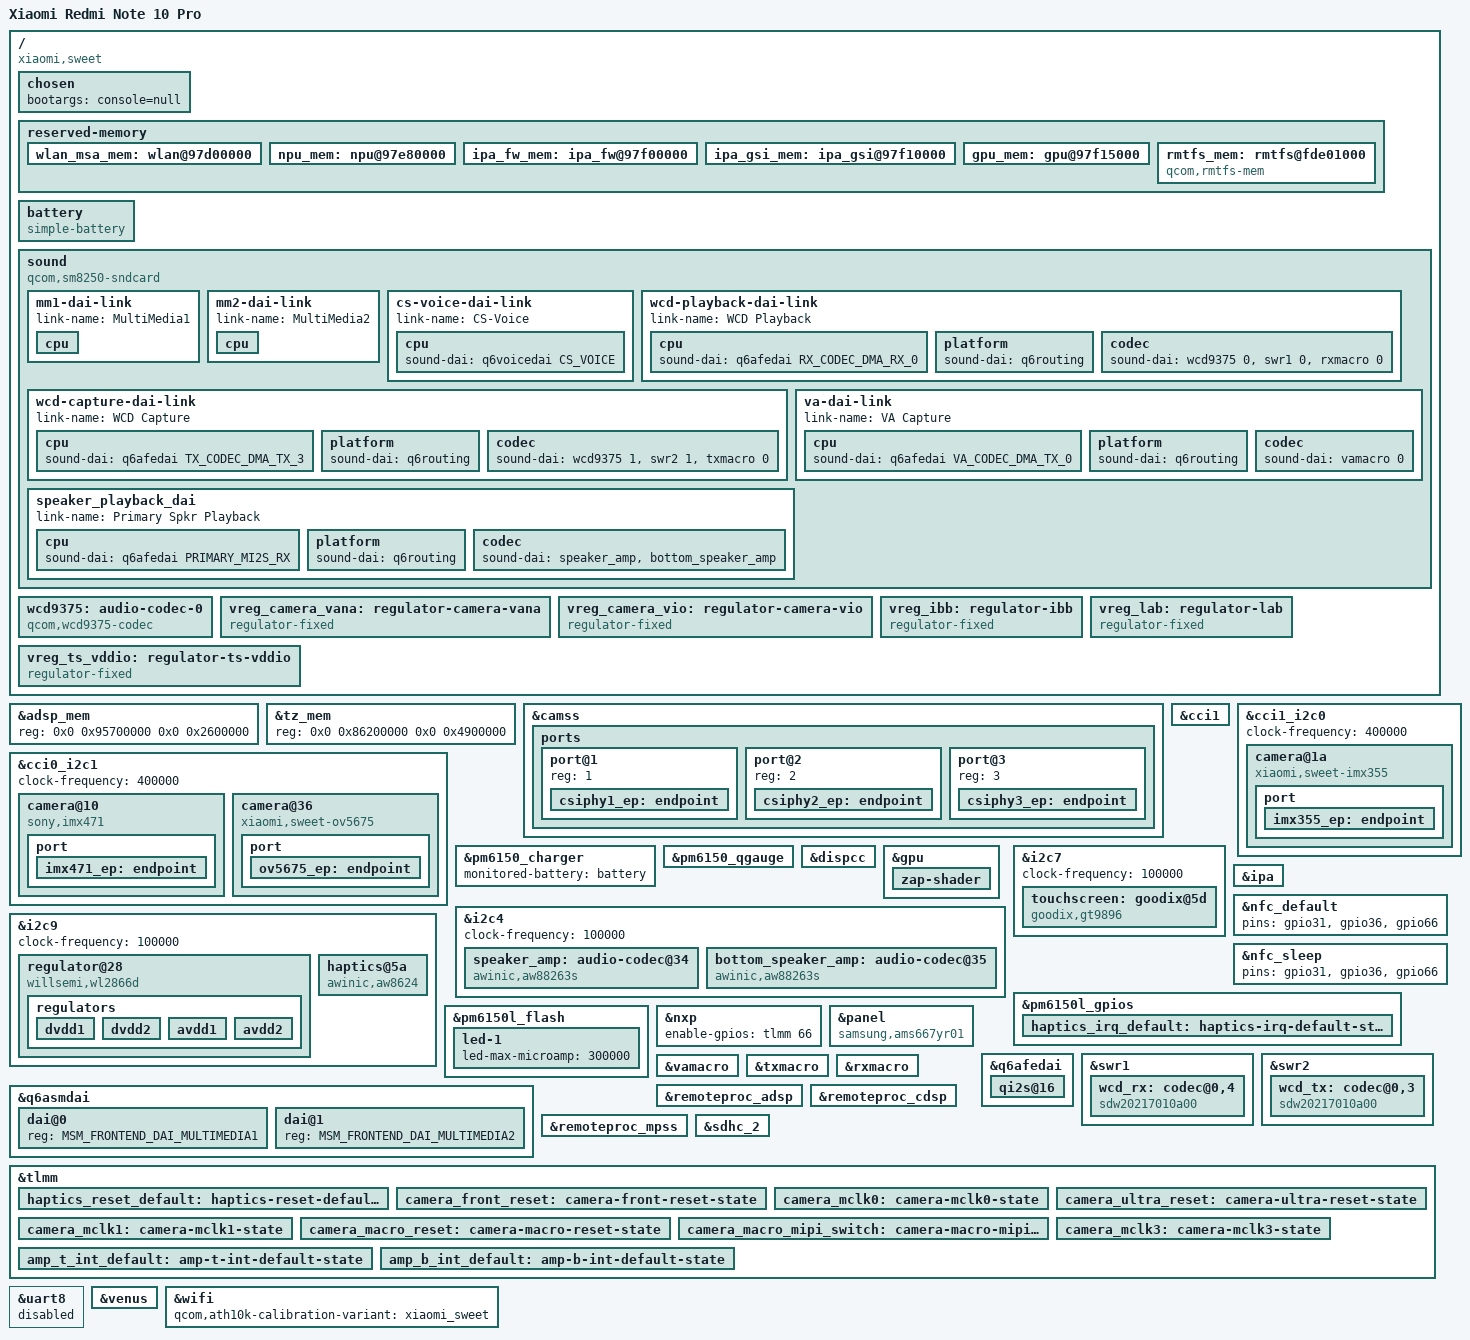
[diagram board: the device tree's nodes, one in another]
// SPDX-License-Identifier: BSD-3-Clause
/*
 * Copyright (c) 2024, Danila Tikhonov <danila@jiaxyga.com>
 * Copyright (c) 2024, Kali Prasad <kprasadvnsi@protonmail.com>
 * Copyright (c) 2024, Salvatore Stella <salvatore.stella@univaq.it>
 */

/dts-v1/;

#include <dt-bindings/sound/qcom,q6voice.h>

#include "sm7150-xiaomi-common.dtsi"

/delete-node/ &wlan_msa_mem;
/delete-node/ &npu_mem;
/delete-node/ &ipa_fw_mem;
/delete-node/ &ipa_gsi_mem;
/delete-node/ &gpu_mem;

&adsp_mem {
	reg = <0x0 0x95700000 0x0 0x2600000>;
};

&tz_mem {
	reg = <0x0 0x86200000 0x0 0x4900000>;
};

/ {
	model = "Xiaomi Redmi Note 10 Pro";
	compatible = "xiaomi,sweet", "qcom,sm7150";

	qcom,board-id = <46 0>;

	chosen {
		/*
		 * Serial engine with the debug UART operates in SPI mode on sweet
		 * So disable console and remove stdout-path
		 */
		/delete-property/ stdout-path;
		bootargs = "console=null";
	};

	reserved-memory {
		wlan_msa_mem: wlan@97d00000 {
			reg = <0x0 0x97d00000 0x0 0x180000>;
			no-map;
		};

		npu_mem: npu@97e80000 {
			reg = <0x0 0x97e80000 0x0 0x80000>;
			no-map;
		};

		ipa_fw_mem: ipa_fw@97f00000 {
			reg = <0x0 0x97f00000 0x0 0x10000>;
			no-map;
		};

		ipa_gsi_mem: ipa_gsi@97f10000 {
			reg = <0x0 0x97f10000 0x0 0x5000>;
			no-map;
		};

		gpu_mem: gpu@97f15000 {
			reg = <0x0 0x97f15000 0x0 0x2000>;
			no-map;
		};

		rmtfs_mem: rmtfs@fde01000 {
			compatible = "qcom,rmtfs-mem";
			reg = <0 0xfde01000 0 0x200000>;
			no-map;

			qcom,client-id = <1>;
			qcom,vmid = <QCOM_SCM_VMID_MSS_MSA>;
		};
	};

	battery: battery {
		compatible = "simple-battery";
		device-chemistry = "lithium-ion-polymer";
		voltage-min-design-microvolt = <3300000>;
		voltage-max-design-microvolt = <4450000>;
		constant-charge-voltage-max-microvolt = <4450000>;
		charge-full-design-microamp-hours = <5020000>;
		/* K6 Sunwoda 5020 mAh SOC_OCV2 profile, verified on sweet.
		 * Converted from the vendor profile: 100 uV and 0.01 percent.
		 */
		ocv-capacity-celsius = <(-10) 0 10 25 40 50>;
		ocv-capacity-table-0 = <4436500 100>, <4409100 98>, <4383600 96>, <4360600 94>,
			<4340100 92>, <4319000 90>, <4295300 88>, <4270400 86>,
			<4245400 84>, <4219900 82>, <4195300 80>, <4173100 78>,
			<4152000 76>, <4129100 74>, <4104000 72>, <4078000 70>,
			<4051600 68>, <4024700 66>, <3998800 64>, <3973200 62>,
			<3949200 60>, <3928400 58>, <3909600 56>, <3892000 54>,
			<3875400 52>, <3859700 50>, <3843800 48>, <3828300 46>,
			<3816900 44>, <3808900 42>, <3802500 40>, <3796600 38>,
			<3791400 36>, <3786000 34>, <3780600 32>, <3775000 30>,
			<3768600 28>, <3761700 26>, <3753900 24>, <3745000 22>,
			<3735300 20>, <3725500 18>, <3715500 16>, <3706300 14>,
			<3697600 12>, <3688500 10>, <3683300 9>, <3676800 8>,
			<3667800 7>, <3651800 6>, <3623000 5>, <3577800 4>,
			<3513100 3>, <3416100 2>, <3254400 1>, <2675700 0>;
		ocv-capacity-table-1 = <4435000 100>, <4408400 98>, <4383200 96>, <4359900 94>,
			<4338600 92>, <4316700 90>, <4292600 88>, <4267400 86>,
			<4242200 84>, <4216800 82>, <4192000 80>, <4168300 78>,
			<4145400 76>, <4122800 74>, <4100800 72>, <4079100 70>,
			<4058000 68>, <4037000 66>, <4013400 64>, <3985000 62>,
			<3957100 60>, <3933600 58>, <3912500 56>, <3893600 54>,
			<3876700 52>, <3861200 50>, <3846500 48>, <3832600 46>,
			<3820300 44>, <3808800 42>, <3799400 40>, <3793700 38>,
			<3789700 36>, <3786000 34>, <3782800 32>, <3779200 30>,
			<3774400 28>, <3767900 26>, <3760100 24>, <3750400 22>,
			<3739000 20>, <3726800 18>, <3713500 16>, <3701700 14>,
			<3691300 12>, <3681600 10>, <3675200 9>, <3667600 8>,
			<3656500 7>, <3640600 6>, <3612800 5>, <3570000 4>,
			<3508000 3>, <3418200 2>, <3261800 1>, <2828800 0>;
		ocv-capacity-table-2 = <4434000 100>, <4411300 98>, <4388900 96>, <4367200 94>,
			<4346400 92>, <4324800 90>, <4301100 88>, <4276600 86>,
			<4252000 84>, <4227300 82>, <4202800 80>, <4178700 78>,
			<4154900 76>, <4131500 74>, <4108600 72>, <4086300 70>,
			<4065500 68>, <4045200 66>, <4022700 64>, <3997000 62>,
			<3971300 60>, <3947300 58>, <3924600 56>, <3905300 54>,
			<3888800 52>, <3874000 50>, <3860700 48>, <3848600 46>,
			<3837500 44>, <3827200 42>, <3817700 40>, <3808500 38>,
			<3799800 36>, <3792000 34>, <3785100 32>, <3779000 30>,
			<3773800 28>, <3769300 26>, <3763400 24>, <3755300 22>,
			<3745200 20>, <3733200 18>, <3719000 16>, <3705300 14>,
			<3694200 12>, <3687500 10>, <3684300 9>, <3680900 8>,
			<3674400 7>, <3658900 6>, <3625100 5>, <3573200 4>,
			<3502700 3>, <3405800 2>, <3249000 1>, <2840100 0>;
		ocv-capacity-table-3 = <4433500 100>, <4411500 98>, <4389800 96>, <4368500 94>,
			<4347800 92>, <4326300 90>, <4302900 88>, <4278600 86>,
			<4254100 84>, <4229300 82>, <4204600 80>, <4180300 78>,
			<4156200 76>, <4132700 74>, <4109800 72>, <4087400 70>,
			<4065800 68>, <4044800 66>, <4024300 64>, <4004700 62>,
			<3983500 60>, <3957100 58>, <3929400 56>, <3908400 54>,
			<3891700 52>, <3877100 50>, <3864000 48>, <3852300 46>,
			<3841500 44>, <3831500 42>, <3822300 40>, <3813600 38>,
			<3805600 36>, <3798100 34>, <3791400 32>, <3784300 30>,
			<3775500 28>, <3766000 26>, <3757000 24>, <3748500 22>,
			<3739200 20>, <3728000 18>, <3715600 16>, <3701600 14>,
			<3692700 12>, <3688900 10>, <3687300 9>, <3685000 8>,
			<3679200 7>, <3658100 6>, <3615000 5>, <3558600 4>,
			<3484400 3>, <3378900 2>, <3209400 1>, <2692400 0>;
		ocv-capacity-table-4 = <4428000 100>, <4406400 98>, <4385000 96>, <4363800 94>,
			<4343100 92>, <4321600 90>, <4298400 88>, <4274200 86>,
			<4249900 84>, <4225300 82>, <4200900 80>, <4176700 78>,
			<4152900 76>, <4129500 74>, <4106800 72>, <4084700 70>,
			<4063200 68>, <4042300 66>, <4022300 64>, <4003500 62>,
			<3983400 60>, <3957800 58>, <3930200 56>, <3909100 54>,
			<3892400 52>, <3878000 50>, <3865000 48>, <3853400 46>,
			<3842800 44>, <3833000 42>, <3824000 40>, <3816000 38>,
			<3808500 36>, <3800500 34>, <3792000 32>, <3782900 30>,
			<3772600 28>, <3761500 26>, <3751300 24>, <3742100 22>,
			<3732600 20>, <3721500 18>, <3709400 16>, <3695700 14>,
			<3687300 12>, <3684400 10>, <3683200 9>, <3680900 8>,
			<3674100 7>, <3648000 6>, <3604000 5>, <3547000 4>,
			<3472300 3>, <3366400 2>, <3202400 1>, <2661500 0>;
		ocv-capacity-table-5 = <4426000 100>, <4404500 98>, <4383100 96>, <4362100 94>,
			<4341300 92>, <4319900 90>, <4296900 88>, <4273000 86>,
			<4248900 84>, <4224400 82>, <4199900 80>, <4175800 78>,
			<4152000 76>, <4128700 74>, <4105800 72>, <4083600 70>,
			<4062400 68>, <4041900 66>, <4022100 64>, <4003500 62>,
			<3983500 60>, <3958300 58>, <3930900 56>, <3909700 54>,
			<3893300 52>, <3878900 50>, <3865900 48>, <3854100 46>,
			<3843300 44>, <3833100 42>, <3823800 40>, <3815600 38>,
			<3808000 36>, <3799600 34>, <3790200 32>, <3780200 30>,
			<3768800 28>, <3756600 26>, <3745800 24>, <3736600 22>,
			<3727200 20>, <3715700 18>, <3703000 16>, <3689400 14>,
			<3681300 12>, <3678700 10>, <3677400 9>, <3675000 8>,
			<3665900 7>, <3637700 6>, <3592000 5>, <3534500 4>,
			<3458600 3>, <3353200 2>, <3168900 1>, <2657400 0>;
	};

	sound {
		compatible = "qcom,sm8250-sndcard";
		pinctrl-0 = <&pri_mi2s_active &pri_mi2s_ws_active>;
		pinctrl-names = "default";
		model = "Redmi Note 10 Pro";
		audio-routing = "AMIC1", "MIC BIAS1",
				"AMIC2", "MIC BIAS2",
				"AMIC3", "MIC BIAS3",
				/* bolero RX macro -> WCD9375 analog inputs */
				"IN1_HPHL", "HPHL_OUT",
				"IN2_HPHR", "HPHR_OUT",
				"IN3_AUX", "AUX_OUT",
				"TX SWR_ADC0", "ADC1_OUTPUT",
				"TX SWR_ADC2", "ADC2_OUTPUT";

		mm1-dai-link {
			link-name = "MultiMedia1";
			cpu {
				sound-dai = <&q6asmdai MSM_FRONTEND_DAI_MULTIMEDIA1>;
			};
		};

		mm2-dai-link {
			link-name = "MultiMedia2";
			cpu {
				sound-dai = <&q6asmdai MSM_FRONTEND_DAI_MULTIMEDIA2>;
			};
		};

		cs-voice-dai-link {
			link-name = "CS-Voice";
			cpu {
				sound-dai = <&q6voicedai CS_VOICE>;
			};
		};

		wcd-playback-dai-link {
			link-name = "WCD Playback";
			cpu {
				sound-dai = <&q6afedai RX_CODEC_DMA_RX_0>;
			};

			platform {
				sound-dai = <&q6routing>;
			};

			codec {
				sound-dai = <&wcd9375 0>, <&swr1 0>, <&rxmacro 0>;
			};
		};

		wcd-capture-dai-link {
			link-name = "WCD Capture";
			cpu {
				sound-dai = <&q6afedai TX_CODEC_DMA_TX_3>;
			};

			platform {
				sound-dai = <&q6routing>;
			};

			codec {
				sound-dai = <&wcd9375 1>, <&swr2 1>, <&txmacro 0>;
			};
		};

		va-dai-link {
			link-name = "VA Capture";
			cpu {
				sound-dai = <&q6afedai VA_CODEC_DMA_TX_0>;
			};

			platform {
				sound-dai = <&q6routing>;
			};

			codec {
				sound-dai = <&vamacro 0>;
			};
		};

		speaker_playback_dai {
			link-name = "Primary Spkr Playback";
			cpu {
				sound-dai = <&q6afedai PRIMARY_MI2S_RX>;
			};

			platform {
				sound-dai = <&q6routing>;
			};

			codec {
				sound-dai = <&speaker_amp>, <&bottom_speaker_amp>;
			};
		};
	};

	wcd9375: audio-codec-0 {
		compatible = "qcom,wcd9375-codec";

		reset-gpios = <&lpass_tlmm 6 GPIO_ACTIVE_LOW>;

		vdd-buck-supply = <&vreg_l15a_1p8>;
		vdd-rxtx-supply = <&vreg_l10a_1p8>;
		vdd-px-supply = <&vreg_l10a_1p8>;
		vdd-mic-bias-supply = <&vreg_bob>;

		qcom,micbias1-microvolt = <2750000>;
		qcom,micbias2-microvolt = <2750000>;
		qcom,micbias3-microvolt = <2750000>;
		qcom,mbhc-buttons-vthreshold-microvolt =
			<75000 150000 237000 500000 500000 500000 500000 500000>;

		qcom,rx-device = <&wcd_rx>;
		qcom,tx-device = <&wcd_tx>;

		#sound-dai-cells = <1>;
	};

	vreg_camera_vana: regulator-camera-vana {
		compatible = "regulator-fixed";
		regulator-name = "camera-vana";
		regulator-min-microvolt = <2800000>;
		regulator-max-microvolt = <2800000>;
		vin-supply = <&vreg_bob>;
		gpio = <&pm6150l_gpios 11 GPIO_ACTIVE_HIGH>;
		enable-active-high;
		startup-delay-us = <100>;
	};

	vreg_camera_vio: regulator-camera-vio {
		compatible = "regulator-fixed";
		regulator-name = "camera-vio";
		regulator-min-microvolt = <1800000>;
		regulator-max-microvolt = <1800000>;
		vin-supply = <&vreg_s5a_2p0>;
		gpio = <&pm6150l_gpios 4 GPIO_ACTIVE_HIGH>;
		enable-active-high;
		startup-delay-us = <100>;
	};

	vreg_ibb: regulator-ibb {
		compatible = "regulator-fixed";
		regulator-name = "ibb";
		regulator-min-microvolt = <6000000>;
		regulator-max-microvolt = <6000000>;
	};

	vreg_lab: regulator-lab {
		compatible = "regulator-fixed";
		regulator-name = "lab";
		regulator-min-microvolt = <6000000>;
		regulator-max-microvolt = <6000000>;
	};

	vreg_ts_vddio: regulator-ts-vddio {
		compatible = "regulator-fixed";
		regulator-name = "vreg_ts_vddio";
		regulator-min-microvolt = <1800000>;
		regulator-max-microvolt = <1800000>;
		gpio = <&tlmm 90 GPIO_ACTIVE_HIGH>;
		enable-active-high;
		regulator-boot-on;
		startup-delay-us = <4000>;
	};
};

&camss {
	ports {
		#address-cells = <1>;
		#size-cells = <0>;

		port@1 {
			reg = <1>;

			csiphy1_ep: endpoint {
				data-lanes = <0 1 2 3>;
				remote-endpoint = <&imx471_ep>;
			};
		};

		port@2 {
			reg = <2>;

			csiphy2_ep: endpoint {
				data-lanes = <0 1 2 3>;
				remote-endpoint = <&imx355_ep>;
			};
		};

		port@3 {
			reg = <3>;

			csiphy3_ep: endpoint {
				data-lanes = <0 1>;
				remote-endpoint = <&ov5675_ep>;
			};
		};
	};
};

&cci0_i2c1 {
	clock-frequency = <400000>;

	camera@10 {
		compatible = "sony,imx471";
		reg = <0x10>;

		clocks = <&camcc CAMCC_MCLK0_CLK>;
		assigned-clocks = <&camcc CAMCC_MCLK0_CLK>;
		assigned-clock-rates = <19200000>;

		reset-gpios = <&tlmm 23 GPIO_ACTIVE_LOW>;
		vana-supply = <&vreg_camera_vana>;
		dovdd-supply = <&vreg_camera_vio>;
		dvdd-supply = <&dvdd2>;

		pinctrl-names = "default";
		pinctrl-0 = <&camera_front_reset &camera_mclk0>;

		orientation = <0>;
		rotation = <90>;

		port {
			imx471_ep: endpoint {
				data-lanes = <0 1 2 3>;
				link-frequencies = /bits/ 64 <702933333>;
				remote-endpoint = <&csiphy1_ep>;
			};
		};
	};

	camera@36 {
		compatible = "xiaomi,sweet-ov5675", "ovti,ov5675";
		reg = <0x36>;

		clocks = <&camcc CAMCC_MCLK3_CLK>;
		assigned-clocks = <&camcc CAMCC_MCLK3_CLK>;
		assigned-clock-rates = <19200000>;

		reset-gpios = <&tlmm 24 GPIO_ACTIVE_LOW>;
		mipi-switch-gpios = <&tlmm 88 GPIO_ACTIVE_HIGH>;
		avdd-supply = <&vreg_camera_vana>;
		dovdd-supply = <&vreg_camera_vio>;
		dvdd-supply = <&dvdd1>;

		pinctrl-names = "default";
		pinctrl-0 = <&camera_macro_reset &camera_macro_mipi_switch
			     &camera_mclk3>;

		orientation = <1>;
		rotation = <270>;

		port {
			ov5675_ep: endpoint {
				data-lanes = <0 1>;
				link-frequencies = /bits/ 64 <450000000>;
				remote-endpoint = <&csiphy3_ep>;
			};
		};
	};
};

&cci1 {
	status = "okay";
};

&cci1_i2c0 {
	clock-frequency = <400000>;

	camera@1a {
		compatible = "xiaomi,sweet-imx355", "sony,imx355";
		reg = <0x1a>;

		clocks = <&camcc CAMCC_MCLK1_CLK>;
		assigned-clocks = <&camcc CAMCC_MCLK1_CLK>;
		assigned-clock-rates = <19200000>;

		reset-gpios = <&tlmm 25 GPIO_ACTIVE_LOW>;
		avdd-supply = <&avdd2>;
		dvdd-supply = <&dvdd1>;
		dovdd-supply = <&vreg_camera_vio>;

		pinctrl-names = "default";
		pinctrl-0 = <&camera_ultra_reset &camera_mclk1>;

		orientation = <1>;
		rotation = <270>;

		port {
			imx355_ep: endpoint {
				data-lanes = <0 1 2 3>;
				link-frequencies = /bits/ 64 <345600000>;
				remote-endpoint = <&csiphy2_ep>;
			};
		};
	};
};

&pm6150_charger {
	monitored-battery = <&battery>;
	status = "okay";
};

&pm6150_qgauge {
	monitored-battery = <&battery>;
	power-supplies = <&pm6150_charger>;
	status = "okay";
};

&dispcc {
	status = "okay";
};

&gpu {
	zap-shader {
		firmware-name = "qcom/sm7150/xiaomi/sweet/a615_zap.mbn";
	};
};

&i2c4 {
	clock-frequency = <100000>;
	status = "okay";

	/* Top speaker */
        speaker_amp: audio-codec@34 {
		compatible = "awinic,aw88263s";
		reg = <0x34>;
		firmware-name = "qcom/sm7150/xiaomi/sweet/aw882xx_pid_2032_acf.bin";

		reset-gpios = <&tlmm 64 GPIO_ACTIVE_HIGH>;

		pinctrl-names = "default";
		pinctrl-0 = <&amp_t_int_default>;

		awinic,audio-channel = <0>;
		awinic,sync-flag;

		sound-name-prefix = "Speaker";
		#sound-dai-cells = <0>;
        };

	/* Bottom speaker */
	bottom_speaker_amp: audio-codec@35 {
		compatible = "awinic,aw88263s";
		reg = <0x35>;
		firmware-name = "qcom/sm7150/xiaomi/sweet/aw882xx_pid_2032_acf.bin";

		reset-gpios = <&tlmm 72 GPIO_ACTIVE_HIGH>;

		pinctrl-names = "default";
		pinctrl-0 = <&amp_b_int_default>;

		awinic,audio-channel = <1>;
		awinic,sync-flag;

		sound-name-prefix = "Bottom Speaker";
		#sound-dai-cells = <0>;
        };
};

&i2c7 {
	clock-frequency = <100000>;
	status = "okay";

	touchscreen: goodix@5d {
		compatible = "goodix,gt9896";
		reg = <0x5d>;
		interrupts-extended = <&tlmm 9 IRQ_TYPE_LEVEL_LOW>;
		reset-gpios = <&tlmm 8 GPIO_ACTIVE_LOW>;
		avdd-supply = <&vreg_l11c_3p3>;
		vddio-supply = <&vreg_ts_vddio>;
		touchscreen-size-x = <1080>;
		touchscreen-size-y = <2400>;
	};
};

&i2c9 {
	clock-frequency = <100000>;
	status = "okay";

	regulator@28 {
		compatible = "willsemi,wl2866d";
		reg = <0x28>;

		vin1-supply = <&vreg_s8c_1p35>;
		vin2-supply = <&vreg_bob>;
		enable-gpios = <&tlmm 30 GPIO_ACTIVE_HIGH>;

		regulators {
			dvdd1: dvdd1 {
				regulator-name = "wl2866d-dvdd1";
				regulator-min-microvolt = <1200000>;
				regulator-max-microvolt = <1200000>;
				regulator-active-discharge = <1>;
			};

			dvdd2: dvdd2 {
				regulator-name = "wl2866d-dvdd2";
				regulator-min-microvolt = <1050000>;
				regulator-max-microvolt = <1050000>;
				regulator-active-discharge = <1>;
			};

			avdd1: avdd1 {
				regulator-name = "wl2866d-avdd1";
				regulator-min-microvolt = <2800000>;
				regulator-max-microvolt = <2800000>;
				regulator-active-discharge = <1>;
			};

			avdd2: avdd2 {
				regulator-name = "wl2866d-avdd2";
				regulator-min-microvolt = <2700000>;
				regulator-max-microvolt = <2700000>;
				regulator-active-discharge = <1>;
			};
		};
	};

	haptics@5a {
		compatible = "awinic,aw8624";
		reg = <0x5a>;
		interrupts-extended = <&pm6150l_gpios 10 IRQ_TYPE_EDGE_FALLING>;
		reset-gpios = <&tlmm 4 GPIO_ACTIVE_LOW>;

		pinctrl-names = "default";
		pinctrl-0 = <&haptics_reset_default &haptics_irq_default>;

		awinic,f0-preset = <2050>;
		awinic,f0-calibration-percent = <7>;
		awinic,drive-level = <106>;
		awinic,overdrive-level = <155>;
		awinic,drive-time = <0xf06c>;
		awinic,zero-cross-threshold = <0x08f8>;
		awinic,brake-cycles = <3>;
		awinic,tset = <0x11>;
		awinic,bemf-upper-threshold = <0x0008>;
		awinic,bemf-lower-threshold = <0x03f8>;
		awinic,f0-trace-parameters = <9 5 1 15>;
	};

	/* lionsemi,ln8000 (charger) @ 51 */
	/* ti,bq2597x (charger) @ 66 */
};

&ipa {
	firmware-name = "qcom/sm7150/xiaomi/sweet/ipa_fws.mbn";
};

&nfc_default {
	pins = "gpio31", "gpio36", "gpio66";
};

&nfc_sleep {
	pins = "gpio31", "gpio36", "gpio66";
};

&pm6150l_gpios {
	haptics_irq_default: haptics-irq-default-state {
		pins = "gpio10";
		function = PMIC_GPIO_FUNC_NORMAL;
		input-enable;
		bias-pull-up;
		power-source = <1>;
		qcom,pull-up-strength = <PMIC_GPIO_PULL_UP_31P5>;
	};
};

&pm6150l_flash {
	status = "okay";

	led-1 {
		led-max-microamp = <300000>;
	};
};

&nxp {
	enable-gpios = <&tlmm 66 GPIO_ACTIVE_HIGH>;
};

&panel {
	compatible = "samsung,ams667yr01";

	vsn-supply = <&vreg_ibb>;
	vsp-supply = <&vreg_lab>;
};

&q6afedai {
	qi2s@16 {
		reg = <PRIMARY_MI2S_RX>;
		qcom,sd-lines = <0>;
	};
};

&q6asmdai {
	dai@0 {
		reg = <MSM_FRONTEND_DAI_MULTIMEDIA1>;
	};

	dai@1 {
		reg = <MSM_FRONTEND_DAI_MULTIMEDIA2>;
	};
};

&swr1 {
	status = "okay";

	wcd_rx: codec@0,4 {
		compatible = "sdw20217010a00";
		reg = <0 4>;

		qcom,rx-port-mapping = <1 2 3 4 5>;
		qcom,rx-channel-mapping = /bits/ 8 <1 2 1 1 2 1 1 2>;
	};
};

&swr2 {
	status = "okay";

	wcd_tx: codec@0,3 {
		compatible = "sdw20217010a00";
		reg = <0 3>;

		qcom,tx-port-mapping = <2 2 3 4>;
		qcom,tx-channel-mapping = /bits/ 8 <1 2 1 1 2 3 3 4 1 2 3 4>;
	};
};

&vamacro {
	status = "okay";
};

&txmacro {
	status = "okay";
};

&rxmacro {
	status = "okay";
};

&remoteproc_adsp {
	firmware-name = "qcom/sm7150/xiaomi/sweet/adsp.mbn";
};

&remoteproc_cdsp {
	firmware-name = "qcom/sm7150/xiaomi/sweet/cdsp.mbn";
};

&remoteproc_mpss {
	firmware-name = "qcom/sm7150/xiaomi/sweet/modem.mbn";
};

&sdhc_2 {
	status = "okay";
};

&tlmm {
	haptics_reset_default: haptics-reset-default-state {
		pins = "gpio4";
		function = "gpio";
		drive-strength = <2>;
		bias-disable;
	};

	camera_front_reset: camera-front-reset-state {
		pins = "gpio23";
		function = "gpio";
		drive-strength = <2>;
		bias-disable;
	};

	camera_mclk0: camera-mclk0-state {
		pins = "gpio13";
		function = "cam_mclk";
		drive-strength = <6>;
		bias-disable;
	};

	camera_ultra_reset: camera-ultra-reset-state {
		pins = "gpio25";
		function = "gpio";
		drive-strength = <2>;
		bias-disable;
	};

	camera_mclk1: camera-mclk1-state {
		pins = "gpio14";
		function = "cam_mclk";
		drive-strength = <4>;
		bias-disable;
	};

	camera_macro_reset: camera-macro-reset-state {
		pins = "gpio24";
		function = "gpio";
		drive-strength = <2>;
		bias-disable;
	};

	camera_macro_mipi_switch: camera-macro-mipi-switch-state {
		pins = "gpio88";
		function = "gpio";
		drive-strength = <2>;
		bias-disable;
	};

	camera_mclk3: camera-mclk3-state {
		pins = "gpio16";
		function = "cam_mclk";
		drive-strength = <6>;
		bias-disable;
	};

	amp_t_int_default: amp-t-int-default-state {
		pins = "gpio93";
		function = "gpio";
		drive-strength = <2>;
		bias-pull-up;
		input-enable;
	};

	amp_b_int_default: amp-b-int-default-state {
		pins = "gpio56";
		function = "gpio";
		drive-strength = <2>;
		bias-pull-up;
		input-enable;
	};
};

&uart8 {
	status = "disabled";
};

&venus {
	status = "okay";
	firmware-name = "qcom/sm7150/xiaomi/sweet/venus.mbn";
};

&wifi {
	qcom,ath10k-calibration-variant = "xiaomi_sweet";
};
